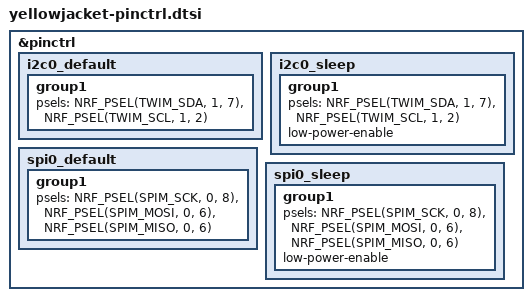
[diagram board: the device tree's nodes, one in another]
&pinctrl {
    i2c0_default: i2c0_default {
        group1 {
            psels =
                <NRF_PSEL(TWIM_SDA, 1, 7)>,
                <NRF_PSEL(TWIM_SCL, 1, 2)>;
        };
    };

    i2c0_sleep: i2c0_sleep {
        group1 {
            psels =
                <NRF_PSEL(TWIM_SDA, 1, 7)>,
                <NRF_PSEL(TWIM_SCL, 1, 2)>;
                low-power-enable;
        };
    };

    spi0_default: spi0_default {
        group1 {
            psels = <NRF_PSEL(SPIM_SCK, 0, 8)>,
                    <NRF_PSEL(SPIM_MOSI, 0, 6)>,
                    <NRF_PSEL(SPIM_MISO, 0, 6)>;
        };
    };

    spi0_sleep: spi0_sleep {
        group1 {
            psels = <NRF_PSEL(SPIM_SCK, 0, 8)>,
                    <NRF_PSEL(SPIM_MOSI, 0, 6)>,
                    <NRF_PSEL(SPIM_MISO, 0, 6)>;
            low-power-enable;
        };
    };
};

